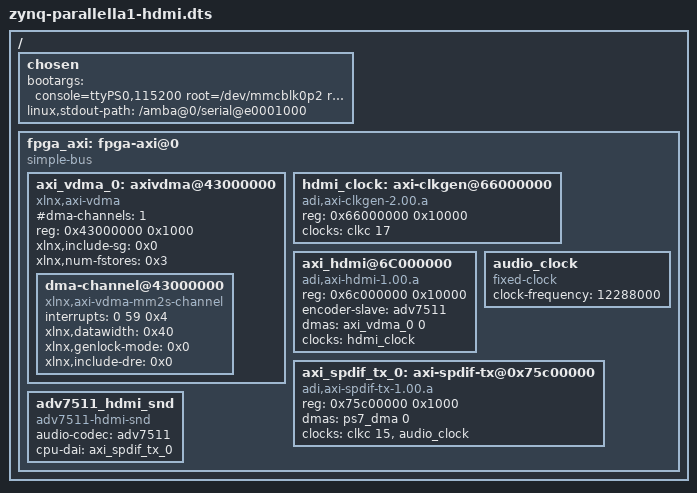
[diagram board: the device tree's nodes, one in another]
/dts-v1/;
/include/ "zynq-parallella1.dtsi"

/ {
       chosen {
	        bootargs = "console=ttyPS0,115200 root=/dev/mmcblk0p2 rw earlyprintk rootfstype=ext4 rootwait";
		//1. bootargs = "console=ttyPS0,115200 root=/dev/mmcblk0p2 rw earlyprintk rootfstype=ext4 rootwait";
	        //2. bootargs = "root=/dev/mmcblk0p2 rw earlyprintk rootfstype=ext4 rootwait";
	        //3. bootargs = "console=ttyPS0,115200 root=/dev/sda1 rw earlyprintk rootfstype=ext4 rootwait";
                linux,stdout-path = "/amba@0/serial@e0001000";
        } ;

	fpga_axi: fpga-axi@0 {
		compatible = "simple-bus";
		#address-cells = <0x1>;
		#size-cells = <0x1>;
		ranges;

		axi_vdma_0: axivdma@43000000 {
			compatible = "xlnx,axi-vdma";
			#address-cells = <1>;
			#size-cells = <1>;
			#dma-cells = <1>;
			#dma-channels = <1>;
			reg = <0x43000000 0x1000>;
			xlnx,include-sg = <0x0>;
			xlnx,num-fstores = <0x3>;
			dma-channel@43000000 {
				compatible = "xlnx,axi-vdma-mm2s-channel";
				interrupts = <0 59 0x4>;
				xlnx,datawidth = <0x40>;
				xlnx,genlock-mode = <0x0>;
				xlnx,include-dre = <0x0>;
			};
		};

		hdmi_clock: axi-clkgen@66000000 {
		        compatible = "adi,axi-clkgen-2.00.a";
			reg = <0x66000000 0x10000>;
			#clock-cells = <0>;
			clocks = <&clkc 17>;
		};

		axi_hdmi@6C000000 {
			compatible = "adi,axi-hdmi-1.00.a";
			reg = <0x6c000000 0x10000>;
			encoder-slave = <&adv7511>;
			dmas = <&axi_vdma_0 0>;
			dma-names = "video";
			clocks = <&hdmi_clock>;
		};

		audio_clock: audio_clock {
			compatible = "fixed-clock";
			#clock-cells = <0>;
			clock-frequency = <12288000>;
		};

		axi_spdif_tx_0: axi-spdif-tx@0x75c00000 {
			compatible = "adi,axi-spdif-tx-1.00.a";
			reg = <0x75c00000 0x1000>;
			dmas = <&ps7_dma 0>;
			dma-names = "tx";
			clocks = <&clkc 15>, <&audio_clock>;
			clock-names = "axi", "spdif";
		};

		adv7511_hdmi_snd: adv7511_hdmi_snd {
			compatible = "adv7511-hdmi-snd";
			audio-codec = <&adv7511>;
			cpu-dai = <&axi_spdif_tx_0>;
		};
	};
};
